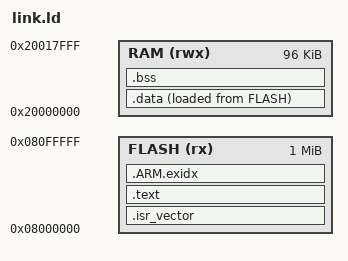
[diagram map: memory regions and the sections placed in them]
/* STM32L475VG: 1 MB flash, SRAM1 96 KB at 0x20000000 (SRAM2 not used). */
MEMORY
{
  FLASH (rx)  : ORIGIN = 0x08000000, LENGTH = 1024K
  RAM   (rwx) : ORIGIN = 0x20000000, LENGTH = 96K
}
_estack = ORIGIN(RAM) + LENGTH(RAM);
ENTRY(Reset_Handler)
SECTIONS
{
  .isr_vector : { KEEP(*(.isr_vector)) } > FLASH
  .text : { *(.text*) *(.rodata*) . = ALIGN(4); } > FLASH
  .ARM.exidx : { *(.ARM.exidx*) } > FLASH
  _sidata = LOADADDR(.data);
  .data : { . = ALIGN(4); _sdata = .; *(.data*) . = ALIGN(4); _edata = .; } > RAM AT > FLASH
  .bss (NOLOAD) : { . = ALIGN(4); _sbss = .; *(.bss*) *(COMMON) . = ALIGN(4); _ebss = .; } > RAM
  end = _ebss; _end = _ebss;
}
